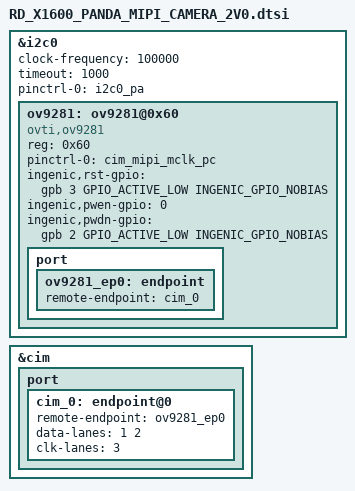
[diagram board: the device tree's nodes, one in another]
&i2c0 {
	status = "okay";
	clock-frequency = <100000>;
	timeout = <1000>;
	pinctrl-names = "default";
	pinctrl-0 = <&i2c0_pa>;

	ov9281:ov9281@0x60 {
		status = "okay";
		compatible = "ovti,ov9281";
		reg = <0x60>;
		pinctrl-names = "default";
		pinctrl-0 = <&cim_mipi_mclk_pc>;

		ingenic,rst-gpio = <&gpb 3 GPIO_ACTIVE_LOW INGENIC_GPIO_NOBIAS>;
		ingenic,pwen-gpio = <0>;
		ingenic,pwdn-gpio = <&gpb 2 GPIO_ACTIVE_LOW INGENIC_GPIO_NOBIAS>;

		port {
			ov9281_ep0:endpoint {
				remote-endpoint = <&cim_0>;
			};
		};
	};
};

&cim {
	status = "okay";
	port {
		cim_0: endpoint@0 {
			remote-endpoint = <&ov9281_ep0>;
			data-lanes = <1 2>;
			clk-lanes = <3>;
		};
	};
};

